# CY8C5667LTI_LP009 register map
File version: 0.1
CY8C56LP
Registers are 8-bit, read-write, no defined reset value unless marked. A register's access mark holds for its fields unless they carry their own. Offsets are from the block's base; lines under a group give offsets from that group; [hi:lo] are bit positions; {n}, {i} and the like mark numbered series; 'fields as' and 'values as' point back to an identical list; <NAME> marks a mode.

## Memory map
0x40004394 USBFS size 0x1D0A
0x400043A3 Timer_UsbSuspend size 0xB64
0x40006407 I2CHW size 0x81
0x40006426 UART_Bridge size 0x49 — UART

## UART_Bridge — UART
Base 0x40006426
0x00 RX_UART_Bridge_RX_ADDRESS1 — RX Address1 Register
0x10 RX_UART_Bridge_RX_ADDRESS2 — RX Address2 Register
0x20 RX_UART_Bridge_RX_DATA — RX Data Register
0x28 TX_UART_Bridge_TX_DATA — TX Data Register
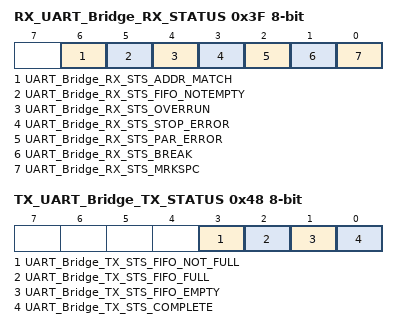
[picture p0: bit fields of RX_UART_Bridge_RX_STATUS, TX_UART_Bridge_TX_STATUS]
0x3F RX_UART_Bridge_RX_STATUS — RX status register
  [6] UART_Bridge_RX_STS_ADDR_MATCH ro, [5] UART_Bridge_RX_STS_FIFO_NOTEMPTY ro, [4] UART_Bridge_RX_STS_OVERRUN ro, [3] UART_Bridge_RX_STS_STOP_ERROR ro, [2] UART_Bridge_RX_STS_PAR_ERROR ro, [1] UART_Bridge_RX_STS_BREAK ro, [0] UART_Bridge_RX_STS_MRKSPC ro
0x48 TX_UART_Bridge_TX_STATUS — TX status register
  [3] UART_Bridge_TX_STS_FIFO_NOT_FULL ro, [2] UART_Bridge_TX_STS_FIFO_FULL ro, [1] UART_Bridge_TX_STS_FIFO_EMPTY ro, [0] UART_Bridge_TX_STS_COMPLETE ro

## Timer_UsbSuspend
Base 0x400043A3
0x00 Timer_UsbSuspend_GLOBAL_ENABLE — PM.ACT.CFG
  [3:0] en_timer — Enable timer/counters.
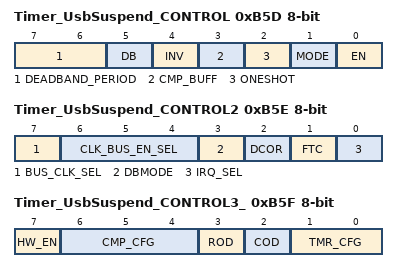
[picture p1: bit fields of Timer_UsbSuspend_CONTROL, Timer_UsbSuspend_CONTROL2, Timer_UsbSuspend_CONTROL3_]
0xB5D Timer_UsbSuspend_CONTROL — TMRx.CFG0
  [7:6] DEADBAND_PERIOD
  [5] DB — Deadband mode--Deadband phases phi1 and phi2 are outputted on CMP and TC output pins respectively.
    0=Timer (CMP and TC are output.); 1=Deadband (PHI1 (instead of CMP) and PHI2 (instead of TC) are output.)
  [4] INV — Invert sense of TIMEREN signal
  [3] CMP_BUFF — Buffer compare register. Compare register updates only on timer terminal count.
  [2] ONESHOT — Timer stops upon reaching stop condition defined by TMR_CFG bits. Can be restarted by asserting TIMER RESET or disabling and re-enabling block.
  [1] MODE — Mode. (0 = Timer; 1 = Comparator)
    0=Timer mode. CNT/CMP register holds timer count value.; 1=Comparator mode. CNT/CMP register holds comparator threshold value.
  [0] EN — Enables timer/comparator.
0xB5E Timer_UsbSuspend_CONTROL2 — TMRx.CFG1
  [7] BUS_CLK_SEL — Bus Clock selection.
  [6:4] CLK_BUS_EN_SEL — Digital Global Clock selection.
  [3] DBMODE — Deadband mode (asynchronous/synchronous). CMP output pin is also affected when not in deadband mode (CFG0.DEADBAND).
  [2] DCOR — Disable Clear on Read (DCOR) of Status Register SR0.
  [1] FTC — First Terminal Count (FTC). Setting this bit forces a single pulse on the TC pin when first enabled.
    0=Disable_FTC (Disable the single cycle pulse, which signifies the timer is starting.); 1=Enable_FTC (Enable the single cycle pulse, which signifies the timer is starting.)
  [0] IRQ_SEL — Irq selection. (0 = raw interrupts; 1 = status register interrupts)
0xB5F Timer_UsbSuspend_CONTROL3_ — TMRx.CFG2
  [7] HW_EN — When set Timer Enable controls counting.
  [6:4] CMP_CFG — Comparator configurations
    0=Equal (Compare Equal); 1=Less_than (Compare Less Than); 2=Less_than_or_equal (Compare Less Than or Equal .); 3=Greater (Compare Greater Than .); 4=Greater_than_or_equal (Compare Greater Than or Equal)
  [3] ROD — Reset On Disable (ROD). Resets internal state of output logic
  [2] COD — Clear On Disable (COD). Clears or gates outputs to zero.
  [1:0] TMR_CFG — Timer configuration (MODE = 0): 000 = Continuous; 001 = Pulsewidth; 010 = Period; 011 = Stop on IRQ
    0=Continuous (Timer runs while EN bit of CFG0 register is set to '1'.); 1=Pulsewidth (Timer runs from positive to negative edge of TIMEREN.); 2=Period (Timer runs from positive to positive edge of TIMEREN.); 3=Irq (Timer runs until IRQ.)
0xB61 Timer_UsbSuspend_PERIOD — TMRx.PER0 - Assigned Period
0xB63 Timer_UsbSuspend_COUNTER — TMRx.CNT_CMP0 - Current Down Counter Value

## I2CHW
Base 0x40006407
0x00 I2CHW_UDB_MSTR_DATA — Data
  [7:0] data — This register provides read/write access to the Shift register.
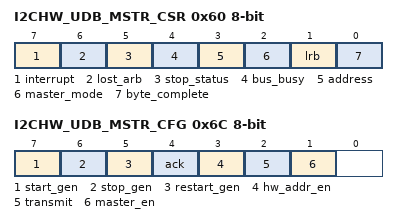
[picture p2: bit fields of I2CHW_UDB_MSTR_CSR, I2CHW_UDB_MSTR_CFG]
0x60 I2CHW_UDB_MSTR_CSR — Status Register
  [7] interrupt ro — Interrupt bit
  [6] lost_arb ro
  [5] stop_status
  [4] bus_busy ro
  [3] address ro
  [2] master_mode ro
  [1] lrb ro
  [0] byte_complete ro
0x6C I2CHW_UDB_MSTR_CFG — Configuration Register
  [7] start_gen, [6] stop_gen, [5] restart_gen, [4] ack, [3] hw_addr_en, [2] transmit, [1] master_en
0x80 I2CHW_UDB_MSTR_INT_MASK — Interrupt Mask

## USBFS
Base 0x40004394
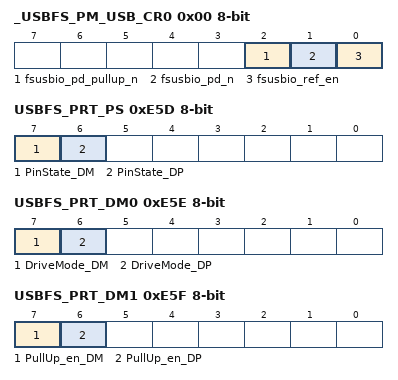
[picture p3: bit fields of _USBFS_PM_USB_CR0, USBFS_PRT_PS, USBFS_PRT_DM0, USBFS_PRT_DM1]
0x00 _USBFS_PM_USB_CR0 — USB Power Mode Control Register 0
  [2] fsusbio_pd_pullup_n, [1] fsusbio_pd_n, [0] fsusbio_ref_en
0x11 USBFS_PM_ACT_CFG — Active Power Mode Configuration Register
0x21 USBFS_PM_STBY_CFG — Standby Power Mode Configuration Register
0xE5D USBFS_PRT_PS — Port Pin State Register
  [7] PinState_DM ro, [6] PinState_DP ro
0xE5E USBFS_PRT_DM0 — Port Drive Mode Register
  [7] DriveMode_DM, [6] DriveMode_DP
0xE5F USBFS_PRT_DM1 — Port Drive Mode Register
  [7] PullUp_en_DM, [6] PullUp_en_DP
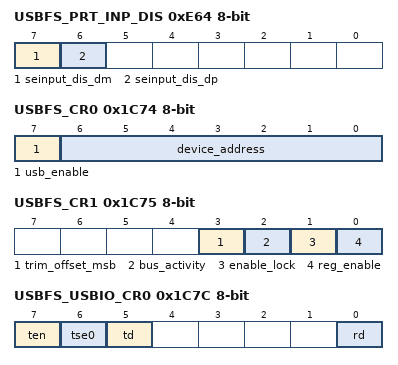
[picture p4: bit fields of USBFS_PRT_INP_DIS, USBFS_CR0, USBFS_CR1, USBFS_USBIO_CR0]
0xE64 USBFS_PRT_INP_DIS — Input buffer disable override
  [7] seinput_dis_dm, [6] seinput_dis_dp
0x1C6C USBFS_EP0_DR0 — bmRequestType
0x1C6D USBFS_EP0_DR1 — bRequest
0x1C6E USBFS_EP0_DR2 — wValueLo
0x1C6F USBFS_EP0_DR3 — wValueHi
0x1C70 USBFS_EP0_DR4 — wIndexLo
0x1C71 USBFS_EP0_DR5 — wIndexHi
0x1C72 USBFS_EP0_DR6 — lengthLo
0x1C73 USBFS_EP0_DR7 — lengthHi
0x1C74 USBFS_CR0 — USB Control Register 0
  [7] usb_enable, [6:0] device_address ro
0x1C75 USBFS_CR1 — USB Control Register 1
  [3] trim_offset_msb, [2] bus_activity, [1] enable_lock, [0] reg_enable
{0x1C6A+0x10*i} USBFS_SIE_EP{i}_CR0 (i=1..8) — The Endpoint{i} Control Register
0x1C7C USBFS_USBIO_CR0 — USBIO Control Register 0
  [7] ten, [6] tse0, [5] td, [0] rd ro
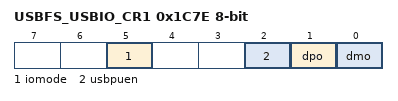
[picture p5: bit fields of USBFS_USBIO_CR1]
0x1C7E USBFS_USBIO_CR1 — USBIO Control Register 1
  [5] iomode, [2] usbpuen, [1] dpo ro, [0] dmo ro
0x1CF8 USBFS_BUF_SIZE — Dedicated Endpoint Buffer Size Register
0x1CFA USBFS_EP_ACTIVE — Endpoint Active Indication Register
0x1CFB USBFS_EP_TYPE — Endpoint Type (IN/OUT) Indication
0x1D09 USBFS_USB_CLK_EN — USB Block Clock Enable Register
